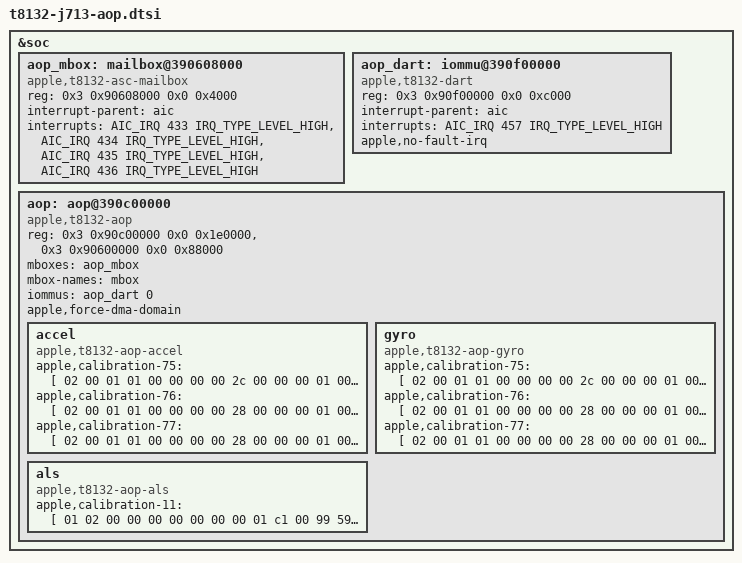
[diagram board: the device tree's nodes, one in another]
// SPDX-License-Identifier: GPL-2.0+ OR MIT
/*
 * Copyright The Asahi Linux Contributors
 * J713 AOP motion and ambient light support from the local M4 bring-up tree.
 */

&soc {
	aop_mbox: mailbox@390608000 {
		compatible = "apple,t8132-asc-mailbox", "apple,asc-mailbox-v4";
		reg = <0x3 0x90608000 0x0 0x4000>;
		interrupt-parent = <&aic>;
		interrupts = <AIC_IRQ 433 IRQ_TYPE_LEVEL_HIGH>,
			     <AIC_IRQ 434 IRQ_TYPE_LEVEL_HIGH>,
			     <AIC_IRQ 435 IRQ_TYPE_LEVEL_HIGH>,
			     <AIC_IRQ 436 IRQ_TYPE_LEVEL_HIGH>;
		interrupt-names = "send-empty", "send-not-empty",
				  "recv-empty", "recv-not-empty";
		#mbox-cells = <0>;
		status = "okay";
	};

	aop_dart: iommu@390f00000 {
		compatible = "apple,t8132-dart", "apple,t8110-dart";
		reg = <0x3 0x90f00000 0x0 0xc000>;
		interrupt-parent = <&aic>;
		interrupts = <AIC_IRQ 457 IRQ_TYPE_LEVEL_HIGH>;
		apple,no-fault-irq;
		#iommu-cells = <1>;
		status = "okay";
	};

	aop: aop@390c00000 {
		compatible = "apple,t8132-aop", "apple,t6020-aop";
		reg = <0x3 0x90c00000 0x0 0x1e0000>,
		      <0x3 0x90600000 0x0 0x88000>;
		mboxes = <&aop_mbox>;
		mbox-names = "mbox";
		iommus = <&aop_dart 0>;
		apple,force-dma-domain;
		status = "okay";

		accel {
			compatible = "apple,t8132-aop-accel", "apple,aop-accel";
			apple,calibration-75 = [
				02 00 01 01 00 00 00 00 2c 00 00 00 01 00 00 00
				10 00 00 00 00 7d 00 00 00 00 00 00 00 00 00 00
				00 00 00 00 00 7d 00 00 00 00 00 00 00 00 00 00
				00 00 00 00 00 7d 00 00 00 00 00 00
			];
			apple,calibration-76 = [
				02 00 01 01 00 00 00 00 28 00 00 00 01 00 00 00
				00 00 00 00 00 00 ff ff 00 00 00 00 00 00 ff ff
				00 00 00 00 00 00 00 00 00 00 00 00 00 00 00 00
				00 00 01 00 00 00 00 00
			];
			apple,calibration-77 = [
				02 00 01 01 00 00 00 00 28 00 00 00 01 00 00 00
				00 00 01 00 00 00 00 00 00 00 00 00 00 00 00 00
				00 00 01 00 00 00 00 00 00 00 00 00 00 00 00 00
				00 00 01 00 00 00 00 00
			];
		};

		gyro {
			compatible = "apple,t8132-aop-gyro", "apple,aop-gyro";
			apple,calibration-75 = [
				02 00 01 01 00 00 00 00 2c 00 00 00 01 00 00 00
				d0 07 00 00 a0 0f 00 00 00 00 00 00 00 00 00 00
				00 00 00 00 a0 0f 00 00 00 00 00 00 00 00 00 00
				00 00 00 00 a0 0f 00 00 00 00 00 00
			];
			apple,calibration-76 = [
				02 00 01 01 00 00 00 00 28 00 00 00 01 00 00 00
				00 00 00 00 00 00 01 00 00 00 00 00 00 00 01 00
				00 00 00 00 00 00 00 00 00 00 00 00 00 00 00 00
				00 00 ff ff 00 00 00 00
			];
			apple,calibration-77 = [
				02 00 01 01 00 00 00 00 28 00 00 00 01 00 00 00
				00 00 01 00 00 00 00 00 00 00 00 00 00 00 00 00
				00 00 01 00 00 00 00 00 00 00 00 00 00 00 00 00
				00 00 01 00 00 00 00 00
			];
		};

		als {
			compatible = "apple,t8132-aop-als", "apple,aop-als";
			apple,calibration-11 = [
				01 02 00 00 00 00 00 00 00 01 c1 00 99 59 fa 00
				64 00 63 00 3e 00 06 06 06 06 05 05 78 b1 03 ba
				3c 38 2b 3b 1f 24 df 3c a0 98 14 3d b6 64 9a 3c
				44 55 a8 46 5c 1b 7f c4 86 85 92 45 8b 81 93 c5
				02 9a 19 45 06 00 00 00 00 0d 00 00 80 00 80 00
				80 00 80 d5 7f eb 7f 1d 80 10 80 af 7f 04 00 00
				00 00 05 00 00 80 00 80 00 80 00 80 f6 7f 01 80
				24 80 1f 80 c0 7f 04 00 00 00 00 0a 00 00 80 00
				80 00 80 00 80 cb 7f 06 80 42 80 50 80 7a 80 07
				00 00 00 00 07 00 00 80 00 80 00 80 00 80 dc 7f
				ff 7f 3c 80 1d 80 1f 80 05 00 00 00 00 09 00 00
				80 00 80 00 80 00 80 cb 7f f0 7f 1b 80 47 80 d8
				7f
			];
		};
	};
};
